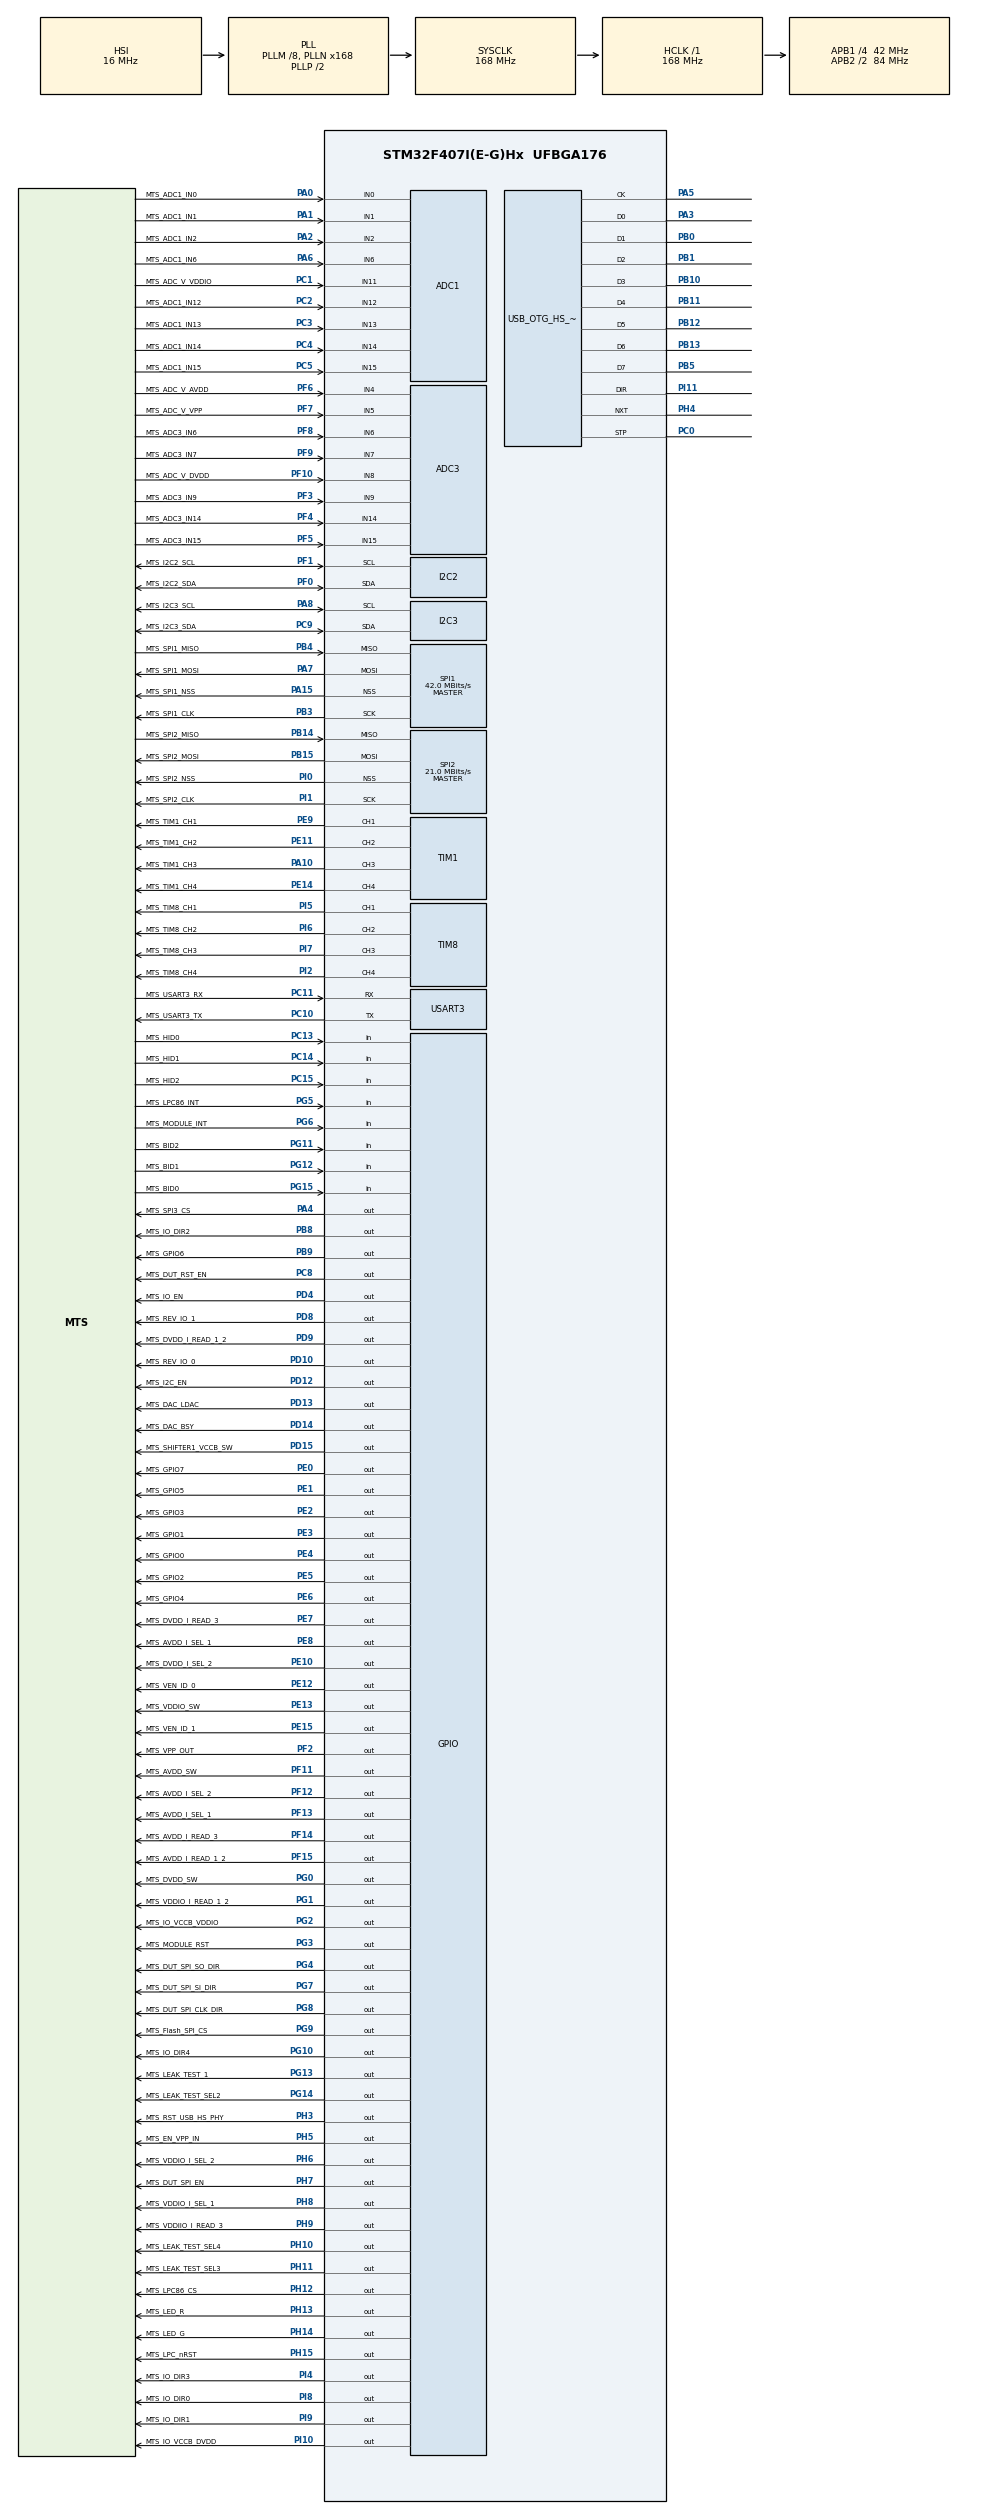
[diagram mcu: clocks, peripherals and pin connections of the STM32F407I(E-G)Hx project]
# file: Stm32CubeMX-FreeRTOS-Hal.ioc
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ADC1.Channel-1\#ChannelRegularConversion=ADC_CHANNEL_0
ADC1.NbrOfConversionFlag=1
ADC1.Rank-1\#ChannelRegularConversion=1
ADC1.SamplingTime-1\#ChannelRegularConversion=ADC_SAMPLETIME_3CYCLES
ADC1.master=1
ADC3.Channel-1\#ChannelRegularConversion=ADC_CHANNEL_4
ADC3.NbrOfConversionFlag=1
ADC3.Rank-1\#ChannelRegularConversion=1
ADC3.SamplingTime-1\#ChannelRegularConversion=ADC_SAMPLETIME_3CYCLES
Dma.Request0=USART3_RX
Dma.Request1=USART3_TX
Dma.USART3_RX.0.Direction=DMA_PERIPH_TO_MEMORY
Dma.USART3_RX.0.FIFOMode=DMA_FIFOMODE_ENABLE
Dma.USART3_RX.0.FIFOThreshold=DMA_FIFO_THRESHOLD_3QUARTERSFULL
Dma.USART3_RX.0.Instance=DMA1_Stream1
Dma.USART3_RX.0.MemBurst=DMA_MBURST_SINGLE
Dma.USART3_RX.0.MemDataAlignment=DMA_MDATAALIGN_BYTE
Dma.USART3_RX.0.MemInc=DMA_MINC_ENABLE
Dma.USART3_RX.0.Mode=DMA_CIRCULAR
Dma.USART3_RX.0.PeriphBurst=DMA_PBURST_SINGLE
Dma.USART3_RX.0.PeriphDataAlignment=DMA_PDATAALIGN_BYTE
Dma.USART3_RX.0.PeriphInc=DMA_PINC_DISABLE
Dma.USART3_RX.0.Priority=DMA_PRIORITY_LOW
Dma.USART3_TX.1.Direction=DMA_MEMORY_TO_PERIPH
Dma.USART3_TX.1.FIFOMode=DMA_FIFOMODE_DISABLE
Dma.USART3_TX.1.Instance=DMA1_Stream3
Dma.USART3_TX.1.MemDataAlignment=DMA_MDATAALIGN_BYTE
Dma.USART3_TX.1.MemInc=DMA_MINC_ENABLE
Dma.USART3_TX.1.Mode=DMA_NORMAL
Dma.USART3_TX.1.PeriphDataAlignment=DMA_PDATAALIGN_BYTE
Dma.USART3_TX.1.PeriphInc=DMA_PINC_DISABLE
Dma.USART3_TX.1.Priority=DMA_PRIORITY_LOW
FREERTOS.Tasks01=DefaultTask,24,512,StartDefaultTask,Default,NULL,Dynamic,NULL,NULL
FREERTOS.configENABLE_BACKWARD_COMPATIBILITY=1
FREERTOS.configMINIMAL_STACK_SIZE=512
FREERTOS.configUSE_IDLE_HOOK=1
I2C2.I2C_Mode=I2C_Fast
I2C3.DualAddressMode=I2C_DUALADDRESS_ENABLE
I2C3.GeneralCallMode=I2C_GENERALCALL_ENABLE
I2C3.I2C_Mode=I2C_Fast
I2C3.OwnAddress=0x5D
I2C3.OwnAddress2=0x14
IWDG.Prescaler=IWDG_PRESCALER_256
Mcu.Family=STM32F4
Mcu.Name=STM32F407I(E-G)Hx
Mcu.Package=UFBGA176
NVIC.DMA1_Stream1_IRQn=true\:5\:0\:false\:false\:true\:true\:false\:true\:true
NVIC.DMA1_Stream3_IRQn=true\:5\:0\:false\:false\:true\:true\:false\:true\:true
NVIC.PriorityGroup=NVIC_PRIORITYGROUP_4
NVIC.TIM7_IRQn=true\:15\:0\:false\:false\:true\:false\:false\:true\:true
NVIC.TimeBase=TIM7_IRQn
NVIC.TimeBaseIP=TIM7
NVIC.USART3_IRQn=true\:5\:0\:false\:false\:true\:true\:true\:true\:true
PA0-WKUP.GPIO_Label=MTS_ADC1_IN0
PA0-WKUP.Signal=ADCx_IN0
PA1.GPIO_Label=MTS_ADC1_IN1
PA1.Signal=ADCx_IN1
PA10.GPIO_Label=MTS_TIM1_CH3
PA10.Signal=S_TIM1_CH3
PA13.Mode=Serial_Wire
PA13.Signal=SYS_JTMS-SWDIO
PA14.Mode=Serial_Wire
PA14.Signal=SYS_JTCK-SWCLK
PA15.GPIO_Label=MTS_SPI1_NSS
PA15.Mode=NSS_Signal_Hard_Output
PA15.Signal=SPI1_NSS
PA2.GPIO_Label=MTS_ADC1_IN2
PA2.Signal=ADCx_IN2
PA3.Mode=Device_HS
PA3.Signal=USB_OTG_HS_ULPI_D0
PA4.GPIO_Label=MTS_SPI3_CS
PA4.Signal=GPIO_Output
PA5.Mode=Device_HS
PA5.Signal=USB_OTG_HS_ULPI_CK
PA6.GPIO_Label=MTS_ADC1_IN6
PA6.Signal=ADCx_IN6
PA7.GPIO_Label=MTS_SPI1_MOSI
PA7.Mode=Full_Duplex_Master
PA7.Signal=SPI1_MOSI
PA8.GPIO_Label=MTS_I2C3_SCL
PA8.Mode=I2C
PA8.Signal=I2C3_SCL
PB0.Mode=Device_HS
PB0.Signal=USB_OTG_HS_ULPI_D1
PB1.Mode=Device_HS
PB1.Signal=USB_OTG_HS_ULPI_D2
PB10.Mode=Device_HS
PB10.Signal=USB_OTG_HS_ULPI_D3
PB11.Mode=Device_HS
PB11.Signal=USB_OTG_HS_ULPI_D4
PB12.Mode=Device_HS
PB12.Signal=USB_OTG_HS_ULPI_D5
PB13.Mode=Device_HS
PB13.Signal=USB_OTG_HS_ULPI_D6
PB14.GPIO_Label=MTS_SPI2_MISO
PB14.Mode=Full_Duplex_Master
PB14.Signal=SPI2_MISO
PB15.GPIO_Label=MTS_SPI2_MOSI
PB15.Mode=Full_Duplex_Master
PB15.Signal=SPI2_MOSI
PB3.GPIO_Label=MTS_SPI1_CLK
PB3.Mode=Full_Duplex_Master
PB3.Signal=SPI1_SCK
PB4.GPIO_Label=MTS_SPI1_MISO
PB4.Mode=Full_Duplex_Master
PB4.Signal=SPI1_MISO
PB5.Mode=Device_HS
PB5.Signal=USB_OTG_HS_ULPI_D7
PB8.GPIO_Label=MTS_IO_DIR2
PB8.Signal=GPIO_Output
PB9.GPIO_Label=MTS_GPIO6
PB9.Signal=GPIO_Output
PC0.Mode=Device_HS
PC0.Signal=USB_OTG_HS_ULPI_STP
PC1.GPIO_Label=MTS_ADC_V_VDDIO
PC1.Signal=ADCx_IN11
PC10.GPIO_Label=MTS_USART3_TX
PC10.Mode=Asynchronous
PC10.Signal=USART3_TX
PC11.GPIO_Label=MTS_USART3_RX
PC11.Mode=Asynchronous
PC11.Signal=USART3_RX
PC13-ANTI_TAMP.GPIO_Label=MTS_HID0
PC13-ANTI_TAMP.Signal=GPIO_Input
PC14-OSC32_IN.GPIO_Label=MTS_HID1
PC14-OSC32_IN.Signal=GPIO_Input
PC15-OSC32_OUT.GPIO_Label=MTS_HID2
PC15-OSC32_OUT.Signal=GPIO_Input
PC2.GPIO_Label=MTS_ADC1_IN12
PC2.Signal=ADCx_IN12
PC3.GPIO_Label=MTS_ADC1_IN13
PC3.Signal=ADCx_IN13
PC4.GPIO_Label=MTS_ADC1_IN14
PC4.Signal=ADCx_IN14
PC5.GPIO_Label=MTS_ADC1_IN15
PC5.Signal=ADCx_IN15
PC8.GPIO_Label=MTS_DUT_RST_EN
PC8.Signal=GPIO_Output
PC9.GPIO_Label=MTS_I2C3_SDA
PC9.Mode=I2C
PC9.Signal=I2C3_SDA
PD10.GPIO_Label=MTS_REV_IO_0
PD10.Signal=GPIO_Output
PD12.GPIO_Label=MTS_I2C_EN
PD12.Signal=GPIO_Output
PD13.GPIO_Label=MTS_DAC_LDAC
PD13.Signal=GPIO_Output
PD14.GPIO_Label=MTS_DAC_BSY
PD14.Signal=GPIO_Output
PD15.GPIO_Label=MTS_SHIFTER1_VCCB_SW
PD15.Signal=GPIO_Output
PD4.GPIO_Label=MTS_IO_EN
PD4.Signal=GPIO_Output
PD8.GPIO_Label=MTS_REV_IO_1
PD8.Signal=GPIO_Output
PD9.GPIO_Label=MTS_DVDD_I_READ_1_2
PD9.Signal=GPIO_Output
PE0.GPIO_Label=MTS_GPIO7
PE0.Signal=GPIO_Output
PE1.GPIO_Label=MTS_GPIO5
PE1.Signal=GPIO_Output
PE10.GPIO_Label=MTS_DVDD_I_SEL_2
PE10.Signal=GPIO_Output
PE11.GPIO_Label=MTS_TIM1_CH2
PE11.Signal=S_TIM1_CH2
PE12.GPIO_Label=MTS_VEN_ID_0
PE12.Signal=GPIO_Output
PE13.GPIO_Label=MTS_VDDIO_SW
PE13.Signal=GPIO_Output
PE14.GPIO_Label=MTS_TIM1_CH4
PE14.Signal=S_TIM1_CH4
PE15.GPIO_Label=MTS_VEN_ID_1
PE15.Signal=GPIO_Output
PE2.GPIO_Label=MTS_GPIO3
PE2.Signal=GPIO_Output
PE3.GPIO_Label=MTS_GPIO1
PE3.Signal=GPIO_Output
PE4.GPIO_Label=MTS_GPIO0
PE4.Signal=GPIO_Output
PE5.GPIO_Label=MTS_GPIO2
PE5.Signal=GPIO_Output
PE6.GPIO_Label=MTS_GPIO4
PE6.Signal=GPIO_Output
PE7.GPIO_Label=MTS_DVDD_I_READ_3
PE7.Signal=GPIO_Output
PE8.GPIO_Label=MTS_AVDD_I_SEL_1
PE8.Signal=GPIO_Output
PE9.GPIO_Label=MTS_TIM1_CH1
PE9.Signal=S_TIM1_CH1
PF0.GPIO_Label=MTS_I2C2_SDA
PF0.Mode=I2C
PF0.Signal=I2C2_SDA
PF1.GPIO_Label=MTS_I2C2_SCL
PF1.Mode=I2C
PF1.Signal=I2C2_SCL
PF10.GPIO_Label=MTS_ADC_V_DVDD
PF10.Mode=IN8
PF10.Signal=ADC3_IN8
PF11.GPIO_Label=MTS_AVDD_SW
PF11.Signal=GPIO_Output
PF12.GPIO_Label=MTS_AVDD_I_SEL_2
PF12.Signal=GPIO_Output
PF13.GPIO_Label=MTS_AVDD_I_SEL_1
PF13.Signal=GPIO_Output
PF14.GPIO_Label=MTS_AVDD_I_READ_3
PF14.Signal=GPIO_Output
PF15.GPIO_Label=MTS_AVDD_I_READ_1_2
PF15.Signal=GPIO_Output
PF2.GPIO_Label=MTS_VPP_OUT
PF2.Signal=GPIO_Output
PF3.GPIO_Label=MTS_ADC3_IN9
PF3.Mode=IN9
PF3.Signal=ADC3_IN9
PF4.GPIO_Label=MTS_ADC3_IN14
PF4.Mode=IN14
PF4.Signal=ADC3_IN14
PF5.GPIO_Label=MTS_ADC3_IN15
PF5.Mode=IN15
PF5.Signal=ADC3_IN15
PF6.GPIO_Label=MTS_ADC_V_AVDD
PF6.Mode=IN4
PF6.Signal=ADC3_IN4
PF7.GPIO_Label=MTS_ADC_V_VPP
PF7.Mode=IN5
PF7.Signal=ADC3_IN5
PF8.GPIO_Label=MTS_ADC3_IN6
PF8.Mode=IN6
PF8.Signal=ADC3_IN6
PF9.GPIO_Label=MTS_ADC3_IN7
PF9.Mode=IN7
PF9.Signal=ADC3_IN7
PG0.GPIO_Label=MTS_DVDD_SW
PG0.Signal=GPIO_Output
PG1.GPIO_Label=MTS_VDDIO_I_READ_1_2
PG1.Signal=GPIO_Output
PG10.GPIO_Label=MTS_IO_DIR4
PG10.Signal=GPIO_Output
PG11.GPIO_Label=MTS_BID2
PG11.Signal=GPIO_Input
PG12.GPIO_Label=MTS_BID1
PG12.Signal=GPIO_Input
PG13.GPIO_Label=MTS_LEAK_TEST_1
PG13.Signal=GPIO_Output
PG14.GPIO_Label=MTS_LEAK_TEST_SEL2
PG14.Signal=GPIO_Output
PG15.GPIO_Label=MTS_BID0
PG15.Signal=GPIO_Input
PG2.GPIO_Label=MTS_IO_VCCB_VDDIO
PG2.Signal=GPIO_Output
PG3.GPIO_Label=MTS_MODULE_RST
PG3.Signal=GPIO_Output
PG4.GPIO_Label=MTS_DUT_SPI_SO_DIR
PG4.Signal=GPIO_Output
PG5.GPIO_Label=MTS_LPC86_INT
PG5.Signal=GPIO_Input
PG6.GPIO_Label=MTS_MODULE_INT
PG6.Signal=GPIO_Input
PG7.GPIO_Label=MTS_DUT_SPI_SI_DIR
PG7.Signal=GPIO_Output
PG8.GPIO_Label=MTS_DUT_SPI_CLK_DIR
PG8.Signal=GPIO_Output
PG9.GPIO_Label=MTS_Flash_SPI_CS
PG9.Signal=GPIO_Output
PH0-OSC_IN.Mode=HSE-External-Oscillator
PH0-OSC_IN.Signal=RCC_OSC_IN
PH1-OSC_OUT.Mode=HSE-External-Oscillator
PH1-OSC_OUT.Signal=RCC_OSC_OUT
PH10.GPIO_Label=MTS_LEAK_TEST_SEL4
PH10.Signal=GPIO_Output
PH11.GPIO_Label=MTS_LEAK_TEST_SEL3
PH11.Signal=GPIO_Output
PH12.GPIO_Label=MTS_LPC86_CS
PH12.Signal=GPIO_Output
PH13.GPIO_Label=MTS_LED_R
PH13.Signal=GPIO_Output
PH14.GPIO_Label=MTS_LED_G
PH14.Signal=GPIO_Output
PH15.GPIO_Label=MTS_LPC_nRST
PH15.Signal=GPIO_Output
PH3.GPIO_Label=MTS_RST_USB_HS_PHY
PH3.Signal=GPIO_Output
PH4.Mode=Device_HS
PH4.Signal=USB_OTG_HS_ULPI_NXT
PH5.GPIO_Label=MTS_EN_VPP_IN
PH5.Signal=GPIO_Output
PH6.GPIO_Label=MTS_VDDIO_I_SEL_2
PH6.Signal=GPIO_Output
PH7.GPIO_Label=MTS_DUT_SPI_EN\\
PH7.Signal=GPIO_Output
PH8.GPIO_Label=MTS_VDDIO_I_SEL_1
PH8.Signal=GPIO_Output
PH9.GPIO_Label=MTS_VDDIIO_I_READ_3
PH9.Signal=GPIO_Output
PI0.GPIO_Label=MTS_SPI2_NSS
PI0.Mode=NSS_Signal_Hard_Output
PI0.Signal=SPI2_NSS
PI1.GPIO_Label=MTS_SPI2_CLK
PI1.Mode=Full_Duplex_Master
PI1.Signal=SPI2_SCK
PI10.GPIO_Label=MTS_IO_VCCB_DVDD
PI10.Signal=GPIO_Output
PI11.Mode=Device_HS
PI11.Signal=USB_OTG_HS_ULPI_DIR
PI2.GPIO_Label=MTS_TIM8_CH4
PI2.Signal=S_TIM8_CH4
PI4.GPIO_Label=MTS_IO_DIR3
PI4.Signal=GPIO_Output
PI5.GPIO_Label=MTS_TIM8_CH1
PI5.Signal=S_TIM8_CH1
PI6.GPIO_Label=MTS_TIM8_CH2
PI6.Signal=S_TIM8_CH2
PI7.GPIO_Label=MTS_TIM8_CH3
PI7.Signal=S_TIM8_CH3
PI8-\ ANTI\ TAMP2.GPIO_Label=MTS_IO_DIR0
PI8-\ ANTI\ TAMP2.Signal=GPIO_Output
PI9.GPIO_Label=MTS_IO_DIR1
PI9.Signal=GPIO_Output
ProjectManager.HeapSize=0x200
ProjectManager.StackSize=0x400
ProjectManager.TargetToolchain=CMake
RCC.48MHZClocksFreq_Value=84000000
RCC.AHBFreq_Value=168000000
RCC.APB1CLKDivider=RCC_HCLK_DIV4
RCC.APB1Freq_Value=42000000
RCC.APB1TimFreq_Value=84000000
RCC.APB2CLKDivider=RCC_HCLK_DIV2
RCC.APB2Freq_Value=84000000
RCC.APB2TimFreq_Value=168000000
RCC.CortexFreq_Value=168000000
RCC.HCLKFreq_Value=168000000
RCC.HSE_VALUE=8000000
RCC.HSI_VALUE=16000000
RCC.LSE_VALUE=32768
RCC.PLLM=8
RCC.PLLN=168
RCC.SYSCLKFreq_VALUE=168000000
RCC.SYSCLKSource=RCC_SYSCLKSOURCE_PLLCLK
RCC.VCOOutputFreq_Value=336000000
SH.ADCx_IN0.0=ADC1_IN0,IN0
SH.ADCx_IN1.0=ADC1_IN1,IN1
SH.ADCx_IN11.0=ADC1_IN11,IN11
SH.ADCx_IN12.0=ADC1_IN12,IN12
SH.ADCx_IN13.0=ADC1_IN13,IN13
SH.ADCx_IN14.0=ADC1_IN14,IN14
SH.ADCx_IN15.0=ADC1_IN15,IN15
SH.ADCx_IN2.0=ADC1_IN2,IN2
SH.ADCx_IN6.0=ADC1_IN6,IN6
SH.S_TIM1_CH1.0=TIM1_CH1,PWM Generation1 CH1
SH.S_TIM1_CH2.0=TIM1_CH2,PWM Generation2 CH2
SH.S_TIM1_CH3.0=TIM1_CH3,PWM Generation3 CH3
SH.S_TIM1_CH4.0=TIM1_CH4,PWM Generation4 CH4
SH.S_TIM8_CH1.0=TIM8_CH1,PWM Generation1 CH1
SH.S_TIM8_CH2.0=TIM8_CH2,PWM Generation2 CH2
SH.S_TIM8_CH3.0=TIM8_CH3,PWM Generation3 CH3
SH.S_TIM8_CH4.0=TIM8_CH4,PWM Generation4 CH4
SPI1.CalculateBaudRate=42.0 MBits/s
SPI1.Direction=SPI_DIRECTION_2LINES
SPI1.Mode=SPI_MODE_MASTER
SPI1.VirtualNSS=VM_NSSHARD
SPI1.VirtualType=VM_MASTER
SPI2.CalculateBaudRate=21.0 MBits/s
SPI2.Direction=SPI_DIRECTION_2LINES
SPI2.Mode=SPI_MODE_MASTER
SPI2.VirtualNSS=VM_NSSHARD
SPI2.VirtualType=VM_MASTER
TIM1.Channel-PWM\ Generation1\ CH1=TIM_CHANNEL_1
TIM1.Channel-PWM\ Generation2\ CH2=TIM_CHANNEL_2
TIM1.Channel-PWM\ Generation3\ CH3=TIM_CHANNEL_3
TIM1.Channel-PWM\ Generation4\ CH4=TIM_CHANNEL_4
TIM1.OCMode_PWM-PWM\ Generation1\ CH1=TIM_OCMODE_PWM1
TIM1.OCMode_PWM-PWM\ Generation2\ CH2=TIM_OCMODE_PWM2
TIM8.Channel-PWM\ Generation1\ CH1=TIM_CHANNEL_1
TIM8.Channel-PWM\ Generation2\ CH2=TIM_CHANNEL_2
TIM8.Channel-PWM\ Generation3\ CH3=TIM_CHANNEL_3
TIM8.Channel-PWM\ Generation4\ CH4=TIM_CHANNEL_4
USART3.VirtualMode=VM_ASYNC
USB_OTG_HS.VirtualMode-Device_HS=Device_HS
VP_CRC_VS_CRC.Mode=CRC_Activate
VP_FREERTOS_VS_CMSIS_V2.Mode=CMSIS_V2
VP_IWDG_VS_IWDG.Mode=IWDG_Activate
VP_RTC_VS_RTC_Activate.Mode=RTC_Enabled
VP_SYS_VS_tim7.Mode=TIM7
VP_TIM1_VS_ClockSourceITR.Mode=TriggerSource_ITR0
VP_TIM1_VS_ControllerModeClock.Mode=Clock Mode
VP_TIM8_VS_ClockSourceITR.Mode=TriggerSource_ITR1
VP_TIM8_VS_ControllerModeClock.Mode=Clock Mode
board=custom

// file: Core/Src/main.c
/* USER CODE BEGIN Header */
/**
  ******************************************************************************
  * @file           : main.c
  * @brief          : Main program body
  ******************************************************************************
  * @attention
  *
  * Copyright (c) 2026 STMicroelectronics.
  * All rights reserved.
  *
  * This software is licensed under terms that can be found in the LICENSE file
  * in the root directory of this software component.
  * If no LICENSE file comes with this software, it is provided AS-IS.
  *
  ******************************************************************************
  */
/* USER CODE END Header */
#include "main.h"
#include "cmsis_os.h"
#include "adc.h"
#include "crc.h"
#include "dma.h"
#include "i2c.h"
#include "iwdg.h"
#include "rtc.h"
#include "spi.h"
#include "tim.h"
#include "usart.h"
#include "usb_otg.h"
#include "gpio.h"

/* USER CODE BEGIN Includes */
#include "semphr.h"
#define LOG_TAG "main"
#include "elog.h"

/* USER CODE END Includes */

/* USER CODE BEGIN PTD */
typedef enum {
  RESET_CAUSE_UNKNOWN = 0,
  RESET_CAUSE_POWER_ON,
  RESET_CAUSE_PIN,
  RESET_CAUSE_SOFTWARE,
  RESET_CAUSE_IWDG,
  RESET_CAUSE_WWDG,
  RESET_CAUSE_BROWNOUT
} reset_cause_t;

/* USER CODE END PTD */

/* USER CODE BEGIN PD */
#define RX_BUF_SIZE 256
/* USER CODE END PD */

/* USER CODE BEGIN PV */
reset_cause_t g_reset_cause = RESET_CAUSE_UNKNOWN;
uint32_t g_reset_flags = 0;

uint8_t usart1_rx_buf[RX_BUF_SIZE];

/* USER CODE END PV */

void SystemClock_Config(void);
void MX_FREERTOS_Init(void);

/* USER CODE BEGIN 0 */
void vApplicationStackOverflowHook(TaskHandle_t xTask, char *pcTaskName)
{
    taskDISABLE_INTERRUPTS();//disable interrupt to avoid the system to reset by WDT
    log_e("Stack overflow in task: %s", pcTaskName);
    __BKPT(0);//set breakpoint to let the user to check the stack overflow issue in debug mode
    //vTaskSuspend(xTask);
    //while(1);
}

void HAL_UART_TxCpltCallback(UART_HandleTypeDef *huart) {
    if (huart->Instance == huart3.Instance) {
        extern osSemaphoreId_t elog_dma_lockHandle;
        osSemaphoreRelease(elog_dma_lockHandle);
    }
}
static void USR_ResetFlag_Get(void){
  g_reset_flags = RCC->CSR;

  if (__HAL_RCC_GET_FLAG(RCC_FLAG_IWDGRST)) {
    g_reset_cause = RESET_CAUSE_IWDG;
  } else if (__HAL_RCC_GET_FLAG(RCC_FLAG_WWDGRST)) {
    g_reset_cause = RESET_CAUSE_WWDG;
  } else if (__HAL_RCC_GET_FLAG(RCC_FLAG_SFTRST)) {
    g_reset_cause = RESET_CAUSE_SOFTWARE;
  } else if (__HAL_RCC_GET_FLAG(RCC_FLAG_BORRST)) {
    g_reset_cause = RESET_CAUSE_BROWNOUT;
  } else if (__HAL_RCC_GET_FLAG(RCC_FLAG_PORRST)) {
    g_reset_cause = RESET_CAUSE_POWER_ON;
  } else if (__HAL_RCC_GET_FLAG(RCC_FLAG_PINRST)) {
    g_reset_cause = RESET_CAUSE_PIN;
  } else {
    g_reset_cause = RESET_CAUSE_UNKNOWN;
  }

  __HAL_RCC_CLEAR_RESET_FLAGS();

}

/* USER CODE END 0 */

int main(void)
{

  /* MCU Configuration--------------------------------------------------------*/

  /* Reset of all peripherals, Initializes the Flash interface and the Systick. */
  HAL_Init();

  /* USER CODE BEGIN Init */
  USR_ResetFlag_Get();
  /* USER CODE END Init */

  /* Configure the system clock */
  SystemClock_Config();

  /* Initialize all configured peripherals */
  MX_GPIO_Init();
  MX_DMA_Init();
  MX_IWDG_Init();
  MX_ADC1_Init();
  MX_ADC3_Init();
  MX_CRC_Init();
  MX_RTC_Init();
  MX_SPI1_Init();
  MX_TIM1_Init();
  MX_I2C2_Init();
  MX_I2C3_Init();
  MX_SPI2_Init();
  MX_TIM8_Init();
  MX_USB_OTG_HS_PCD_Init();
  MX_USART3_UART_Init();
  /* USER CODE BEGIN 2 */

#if 1
  elog_init();
  elog_set_fmt(ELOG_LVL_ASSERT, ELOG_FMT_ALL & ~ELOG_FMT_P_INFO);
  elog_set_fmt(ELOG_LVL_ERROR, ELOG_FMT_LVL | ELOG_FMT_TAG | ELOG_FMT_TIME);
  elog_set_fmt(ELOG_LVL_WARN, ELOG_FMT_LVL | ELOG_FMT_TAG | ELOG_FMT_TIME);
  elog_set_fmt(ELOG_LVL_INFO, ELOG_FMT_LVL | ELOG_FMT_TAG | ELOG_FMT_TIME);
  elog_set_fmt(ELOG_LVL_DEBUG, ELOG_FMT_ALL & ~(ELOG_FMT_FUNC | ELOG_FMT_P_INFO));
  elog_set_fmt(ELOG_LVL_VERBOSE, ELOG_FMT_ALL & ~(ELOG_FMT_FUNC | ELOG_FMT_P_INFO));
  elog_start();
  log_i("reset cause: %d, reset flags: 0x%08lx", g_reset_cause, g_reset_flags);

  size_t HCLK = HAL_RCC_GetHCLKFreq();
  log_i("SystemCoreClock=%lu", SystemCoreClock);
  log_i("HCLK=%lu", HCLK);
  log_i("Systick LOAD=%lu", SysTick->LOAD);
  log_i("Systick CTRL=0x%08lx", SysTick->CTRL);
#endif
  /* USER CODE END 2 */

  /* Init scheduler */
  osKernelInitialize();  /* Call init function for freertos objects (in cmsis_os2.c) */
  MX_FREERTOS_Init();

  /* Start scheduler */
  osKernelStart();

  /* We should never get here as control is now taken by the scheduler */

  /* Infinite loop */
  while (1)
  {

  }
}

void SystemClock_Config(void)
{
  RCC_OscInitTypeDef RCC_OscInitStruct = {0};
  RCC_ClkInitTypeDef RCC_ClkInitStruct = {0};

  /** Configure the main internal regulator output voltage
  */
  __HAL_RCC_PWR_CLK_ENABLE();
  __HAL_PWR_VOLTAGESCALING_CONFIG(PWR_REGULATOR_VOLTAGE_SCALE1);

  /** Initializes the RCC Oscillators according to the specified parameters
  * in the RCC_OscInitTypeDef structure.
  */
  RCC_OscInitStruct.OscillatorType = RCC_OSCILLATORTYPE_HSI|RCC_OSCILLATORTYPE_LSI;
  RCC_OscInitStruct.HSIState = RCC_HSI_ON;
  RCC_OscInitStruct.HSICalibrationValue = RCC_HSICALIBRATION_DEFAULT;
  RCC_OscInitStruct.LSIState = RCC_LSI_ON;
  RCC_OscInitStruct.PLL.PLLState = RCC_PLL_ON;
  RCC_OscInitStruct.PLL.PLLSource = RCC_PLLSOURCE_HSI;
  RCC_OscInitStruct.PLL.PLLM = 8;
  RCC_OscInitStruct.PLL.PLLN = 168;
  RCC_OscInitStruct.PLL.PLLP = RCC_PLLP_DIV2;
  RCC_OscInitStruct.PLL.PLLQ = 4;
  if (HAL_RCC_OscConfig(&RCC_OscInitStruct) != HAL_OK)
  {
    Error_Handler();
  }

  /** Initializes the CPU, AHB and APB buses clocks
  */
  RCC_ClkInitStruct.ClockType = RCC_CLOCKTYPE_HCLK|RCC_CLOCKTYPE_SYSCLK
                              |RCC_CLOCKTYPE_PCLK1|RCC_CLOCKTYPE_PCLK2;
  RCC_ClkInitStruct.SYSCLKSource = RCC_SYSCLKSOURCE_PLLCLK;
  RCC_ClkInitStruct.AHBCLKDivider = RCC_SYSCLK_DIV1;
  RCC_ClkInitStruct.APB1CLKDivider = RCC_HCLK_DIV4;
  RCC_ClkInitStruct.APB2CLKDivider = RCC_HCLK_DIV2;

  if (HAL_RCC_ClockConfig(&RCC_ClkInitStruct, FLASH_LATENCY_5) != HAL_OK)
  {
    Error_Handler();
  }
}

void HAL_TIM_PeriodElapsedCallback(TIM_HandleTypeDef *htim)
{
  if (htim->Instance == TIM7)
  {
    HAL_IncTick();
  }
}

void Error_Handler(void)
{
  __disable_irq();
  while (1)
  {
  }
}

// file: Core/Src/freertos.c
/* USER CODE BEGIN Header */
/**
  ******************************************************************************
  * File Name          : freertos.c
  * Description        : Code for freertos applications
  ******************************************************************************
  * @attention
  *
  * Copyright (c) 2026 STMicroelectronics.
  * All rights reserved.
  *
  * This software is licensed under terms that can be found in the LICENSE file
  * in the root directory of this software component.
  * If no LICENSE file comes with this software, it is provided AS-IS.
  *
  ******************************************************************************
  */
/* USER CODE END Header */

#include "FreeRTOS.h"
#include "task.h"
#include "main.h"
#include "cmsis_os.h"

/* USER CODE BEGIN Includes */
#include "semphr.h"
#include "app_watchdog_task.h"
#include "board_access_task.h"
#define LOG_TAG "FreeRTOS"
#include "elog.h"

/* USER CODE END Includes */

/* USER CODE BEGIN PTD */
typedef StaticTask_t osStaticThreadDef_t;

/* USER CODE END PTD */

/* USER CODE BEGIN Variables */
/* Definitions for LedTask */
const osThreadAttr_t LedTask_attributes = {
  .name = "LedTask",
  .stack_size = 512 * 4,
  .priority = (osPriority_t) osPriorityNormal,
};
/* Definitions for elog */
osThreadId_t elogHandle;
uint32_t elogBuffer[ 256 ];//ELOG_LINE_BUF_SIZE*2*4 bytes
osStaticThreadDef_t elogControlBlock;
const osThreadAttr_t elog_attributes = {
  .name = "elog",
  .stack_mem = &elogBuffer[0],
  .stack_size = sizeof(elogBuffer),
  .cb_mem = &elogControlBlock,
  .cb_size = sizeof(elogControlBlock),
  .priority = (osPriority_t) osPriorityLow,
};
/* Definitions for BoardAccessTask */
osThreadId_t BoardAccessTaskHandle;
const osThreadAttr_t BoardAccessTask_attributes = {
  .name = "BoardAccess",
  .stack_size = 256 * 4,
  .priority = (osPriority_t) osPriorityAboveNormal,
};
/* Definitions for elog_lock */
osSemaphoreId_t elog_lockHandle;
const osSemaphoreAttr_t elog_lock_attributes = {
  .name = "elog_lock"
};
/* Definitions for elog_async */
osSemaphoreId_t elog_asyncHandle;
const osSemaphoreAttr_t elog_async_attributes = {
  .name = "elog_async"
};
/* Definitions for elog_dma_lock */
osSemaphoreId_t elog_dma_lockHandle;
const osSemaphoreAttr_t elog_dma_lock_attributes = {
  .name = "elog_dma_lock"
};
/* freertos.c */

/* USER CODE END Variables */
/* Definitions for DefaultTask */
osThreadId_t DefaultTaskHandle;
const osThreadAttr_t DefaultTask_attributes = {
  .name = "DefaultTask",
  .stack_size = 512 * 4,
  .priority = (osPriority_t) osPriorityNormal,
};

/* USER CODE BEGIN FunctionPrototypes */
extern void elog_entry(void *argument);
void vStartLedTask(void *argument);

/* USER CODE END FunctionPrototypes */

void StartDefaultTask(void *argument);

void MX_FREERTOS_Init(void); /* (MISRA C 2004 rule 8.1) */

/* Hook prototypes */
void vApplicationIdleHook(void);

/* USER CODE BEGIN 2 */
void vApplicationIdleHook( void )
{
   /* vApplicationIdleHook() will only be called if configUSE_IDLE_HOOK is set
   to 1 in FreeRTOSConfig.h. It will be called on each iteration of the idle
   task. It is essential that code added to this hook function never attempts
   to block in any way (for example, call xQueueReceive() with a block time
   specified, or call vTaskDelay()). If the application makes use of the
   vTaskDelete() API function (as this demo application does) then it is also
   important that vApplicationIdleHook() is permitted to return to its calling
   function, because it is the responsibility of the idle task to clean up
   memory allocated by the kernel to any task that has since been deleted. */
}
/* USER CODE END 2 */

void MX_FREERTOS_Init(void) {

  /* USER CODE BEGIN RTOS_SEMAPHORES */
  /* add semaphores, ... */
  /* Create the semaphores(s) */
  /* creation of elog_lock */
  elog_lockHandle = osSemaphoreNew(1, 1, &elog_lock_attributes);

  /* creation of elog_async */
  elog_asyncHandle = osSemaphoreNew(1, 1, &elog_async_attributes);

  /* creation of elog_dma_lock */
  elog_dma_lockHandle = osSemaphoreNew(1, 1, &elog_dma_lock_attributes);

  Watchdog_Init();
  /* USER CODE END RTOS_SEMAPHORES */

  /* Create the thread(s) */
  /* creation of DefaultTask */
  DefaultTaskHandle = osThreadNew(StartDefaultTask, NULL, &DefaultTask_attributes);

  /* USER CODE BEGIN RTOS_THREADS */
  /* add threads, ... */
  /* creation of LedTask */
  osThreadId_t LedTaskHandle = osThreadNew(vStartLedTask, NULL, &LedTask_attributes);

  /* creation of BoardAccessTask */
  BoardAccessTaskHandle = osThreadNew(vBoardAccessTask, NULL, &BoardAccessTask_attributes);

  osThreadId_t watchdogTaskHandle = osThreadNew(vStartWatchdogTask, NULL, &(osThreadAttr_t){
      .name = "watchdogTask",
      .priority = osPriorityBelowNormal,
      .stack_size = 512*4
    });

  /* creation of elog */
  elogHandle = osThreadNew(elog_entry, NULL, &elog_attributes);

  /* USER CODE END RTOS_THREADS */

}

void StartDefaultTask(void *argument)
{
  /* USER CODE BEGIN StartDefaultTask */
  Watchdog_RegisterTask(xTaskGetCurrentTaskHandle(),pcTaskGetTaskName(xTaskGetCurrentTaskHandle()));
  /* Infinite loop */
  for(;;)
  {
    Watchdog_ReportAlive(xTaskGetCurrentTaskHandle());
    osDelay(1000);
    log_e("running: default task");
  }
  /* USER CODE END StartDefaultTask */
}

/* USER CODE BEGIN Application */
/* USER CODE BEGIN Header_StartLedTask */
/**
  * @brief  Function implementing the LedTask thread.
  * @param  argument: Not used
  * @retval None
  */
/* USER CODE END Header_StartLedTask */
void vStartLedTask(void *argument)
{
  /* USER CODE BEGIN 5 */
  Watchdog_RegisterTask(xTaskGetCurrentTaskHandle(), pcTaskGetTaskName(xTaskGetCurrentTaskHandle()));
  /* Infinite loop */
  for (;;) {
    HAL_GPIO_TogglePin(MTS_LED_G_GPIO_Port, MTS_LED_G_Pin);
    Watchdog_ReportAlive(xTaskGetCurrentTaskHandle());
    osDelay(1000);//HAL_Delay(1000);
    HAL_GPIO_TogglePin(MTS_LED_R_GPIO_Port, MTS_LED_R_Pin);
    Watchdog_ReportAlive(xTaskGetCurrentTaskHandle());
    osDelay(1000);
	  log_i("running: led task");
  }
  /* USER CODE END 5 */
}

/* USER CODE END Application */
